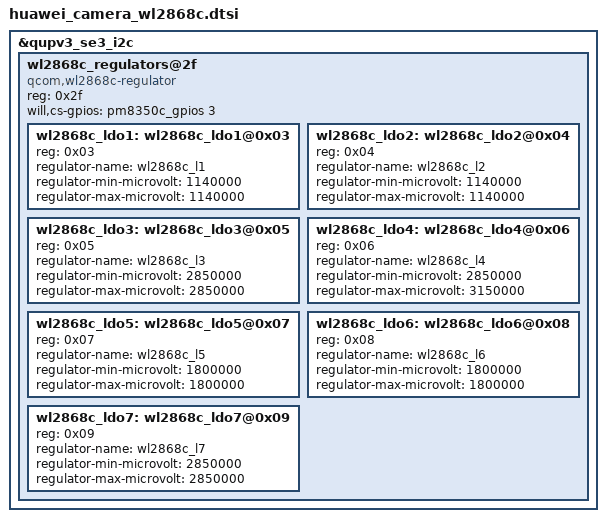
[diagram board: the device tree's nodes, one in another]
&qupv3_se3_i2c {
	status = "ok";
	wl2868c_regulators@2f {
		compatible = "qcom,wl2868c-regulator";
		reg = <0x2f>;
		will,cs-gpios = <&pm8350c_gpios 3 0>;
			wl2868c_ldo1: wl2868c_ldo1@0x03 {
				reg = /bits/ 16 <0x03>;
				regulator-name = "wl2868c_l1";
				regulator-min-microvolt = <1140000>;
				regulator-max-microvolt = <1140000>;
			};
			wl2868c_ldo2: wl2868c_ldo2@0x04 {
				reg = /bits/ 16 <0x04>;
				regulator-name = "wl2868c_l2";
				regulator-min-microvolt = <1140000>;
				regulator-max-microvolt = <1140000>;
			};
			wl2868c_ldo3: wl2868c_ldo3@0x05 {
				reg = /bits/ 16 <0x05>;
				regulator-name = "wl2868c_l3";
				regulator-min-microvolt = <2850000>;
				regulator-max-microvolt = <2850000>;
			};
			wl2868c_ldo4: wl2868c_ldo4@0x06 {
				reg = /bits/ 16 <0x06>;
				regulator-name = "wl2868c_l4";
				regulator-min-microvolt = <2850000>;
				regulator-max-microvolt = <3150000>;
			};
			wl2868c_ldo5: wl2868c_ldo5@0x07 {
				reg = /bits/ 16 <0x07>;
				regulator-name = "wl2868c_l5";
				regulator-min-microvolt = <1800000>;
				regulator-max-microvolt = <1800000>;
			};
			wl2868c_ldo6: wl2868c_ldo6@0x08 {
				reg = /bits/ 16 <0x08>;
				regulator-name = "wl2868c_l6";
				regulator-min-microvolt = <1800000>;
				regulator-max-microvolt = <1800000>;
			};
			wl2868c_ldo7: wl2868c_ldo7@0x09 {
				reg = /bits/ 16 <0x09>;
				regulator-name = "wl2868c_l7";
				regulator-min-microvolt = <2850000>;
				regulator-max-microvolt = <2850000>;
			};
	};
};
